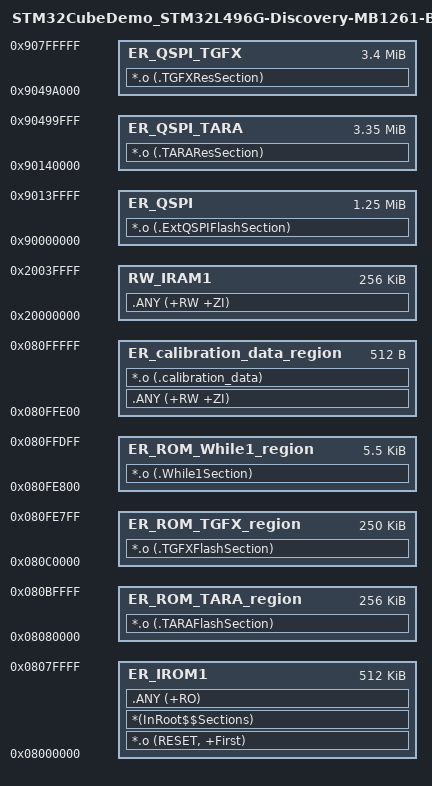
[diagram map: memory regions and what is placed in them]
; *************************************************************
; *** Scatter-Loading Description File generated by uVision ***
; *************************************************************

LR_IROM1 0x08000000 0x100000   {    ; load region size_region
  ER_IROM1 0x08000000 0x80000 {  ; load address = execution address
   *.o (RESET, +First)
   *(InRoot$$Sections)
   .ANY (+RO)
  } 
   RW_IRAM1 0x20000000 0x40000  {  ; RW data
   .ANY (+RW +ZI)
  }
  } 
LR_ROM_TARA_region 0x08080000 0x40000  {
  ER_ROM_TARA_region 0x08080000 0x40000  {
   *.o (.TARAFlashSection)
  }
  }
  LR_ROM_TGFX_region 0x080C0000 0x3E800  {
    ER_ROM_TGFX_region 0x080C0000 0x3E800  {
   *.o (.TGFXFlashSection)
  }
  }
  
LR_ROM_While1_region 0x080FE800 0x1600  {
ER_ROM_While1_region 0x080FE800 0x1600  {
   *.o (.While1Section)
  }
  }  
LR_calibration_data_region 0x080FFE00 0x200  {
  ER_calibration_data_region 0x080FFE00 0x200  {
    .ANY (+RW +ZI)
   *.o (.calibration_data)
  }
  }  
  
LR_QSPI 0x90000000 0x140000 {
  ER_QSPI 0x90000000 0x140000 {
  *.o (.ExtQSPIFlashSection)
  }
  }
LR_QSPI_TARA 0x90140000 0x35A000 {
  ER_QSPI_TARA 0x90140000 0x35A000 {
  *.o (.TARAResSection)
  }
  }  
LR_QSPI_TGFX 0x9049A000 0x366000 {
ER_QSPI_TGFX 0x9049A000 0x366000 {
  *.o (.TGFXResSection)
  }
  }   



